# apps_rcm register map
Vendor: Texas Instruments
Peripheral module from a debugger description file (folder cc32).
Registers are 32-bit, read-write, no defined reset value unless marked. A register's access mark holds for its fields unless they carry their own. Offsets are as the file gives them; lines under a group give offsets from that group; [hi:lo] are bit positions; {n}, {i} and the like mark numbered series; 'fields as' and 'values as' point back to an identical list; <NAME> marks a mode.

## apps_rcm
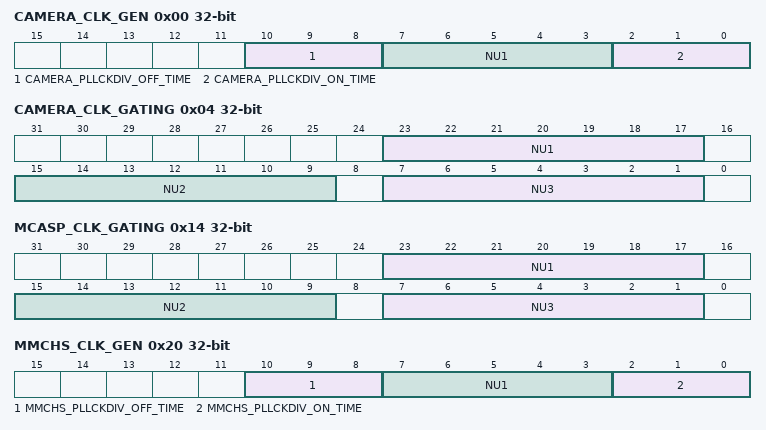
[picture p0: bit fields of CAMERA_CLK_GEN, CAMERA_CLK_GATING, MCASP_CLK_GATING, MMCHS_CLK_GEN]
0x00 CAMERA_CLK_GEN
  [10:8] CAMERA_PLLCKDIV_OFF_TIME — Configuration of OFF-TIME for dividing PLL clk (240 MHz) in generation of Camera func-clk : "000" - 1 "001" - 2 "010" - 3 "011" - 4 "100" - 5 "101" - 6 "110" - 7 "111" - 8
  [7:3] NU1
  [2:0] CAMERA_PLLCKDIV_ON_TIME — Configuration of ON-TIME for dividing PLL clk (240 MHz) in generation of Camera func-clk : "000" - 1 "001" - 2 "010" - 3 "011" - 4 "100" - 5 "101" - 6 "110" - 7 "111" - 8
0x04 CAMERA_CLK_GATING
  [23:17] NU1, [15:9] NU2, [7:1] NU3
0x08 CAMERA_SOFT_RESET access not given
0x14 MCASP_CLK_GATING
  [23:17] NU1, [15:9] NU2, [7:1] NU3
0x18 MCASP_SOFT_RESET access not given
0x20 MMCHS_CLK_GEN
  [10:8] MMCHS_PLLCKDIV_OFF_TIME — Configuration of OFF-TIME for dividing PLL clk (240 MHz) in generation of MMCHS func-clk : "000" - 1 "001" - 2 "010" - 3 "011" - 4 "100" - 5 "101" - 6 "110" - 7 "111" - 8
  [7:3] NU1
  [2:0] MMCHS_PLLCKDIV_ON_TIME — Configuration of ON-TIME for dividing PLL clk (240 MHz) in generation of MMCHS func-clk : "000" - 1 "001" - 2 "010" - 3 "011" - 4 "100" - 5 "101" - 6 "110" - 7 "111" - 8
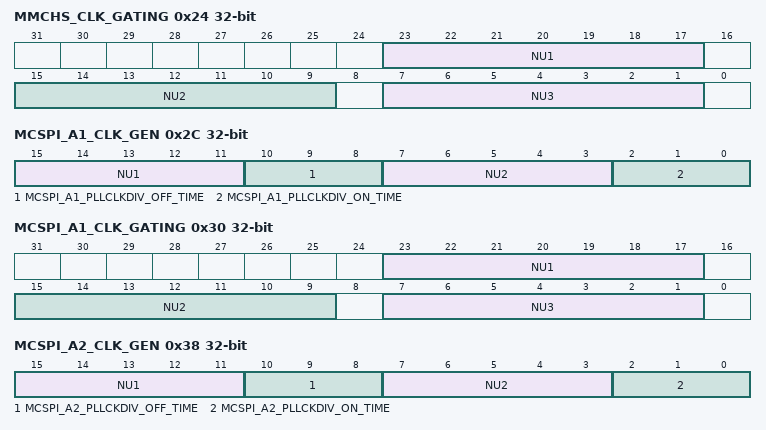
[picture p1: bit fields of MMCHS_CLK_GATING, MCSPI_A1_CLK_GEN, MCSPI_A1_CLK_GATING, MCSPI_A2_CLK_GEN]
0x24 MMCHS_CLK_GATING
  [23:17] NU1, [15:9] NU2, [7:1] NU3
0x28 MMCHS_SOFT_RESET access not given
0x2C MCSPI_A1_CLK_GEN
  [15:11] NU1
  [10:8] MCSPI_A1_PLLCLKDIV_OFF_TIME — Configuration of OFF-TIME for dividing PLL clk (240 MHz) in generation of MCSPI_A1 func-clk : "000" - 1 "001" - 2 "010" - 3 "011" - 4 "100" - 5 "101" - 6 "110" - 7 "111" - 8
  [7:3] NU2
  [2:0] MCSPI_A1_PLLCLKDIV_ON_TIME — Configuration of ON-TIME for dividing PLL clk (240 MHz) in generation of MCSPI_A1 func-clk : "000" - 1 "001" - 2 "010" - 3 "011" - 4 "100" - 5 "101" - 6 "110" - 7 "111" - 8
0x30 MCSPI_A1_CLK_GATING
  [23:17] NU1, [15:9] NU2, [7:1] NU3
0x34 MCSPI_A1_SOFT_RESET access not given
0x38 MCSPI_A2_CLK_GEN
  [15:11] NU1
  [10:8] MCSPI_A2_PLLCKDIV_OFF_TIME — Configuration of OFF-TIME for dividing PLL clk (240 MHz) in generation of MCSPI_A2 func-clk : "000" - 1 "001" - 2 "010" - 3 "011" - 4 "100" - 5 "101" - 6 "110" - 7 "111" - 8
  [7:3] NU2
  [2:0] MCSPI_A2_PLLCKDIV_ON_TIME — Configuration of OFF-TIME for dividing PLL clk (240 MHz) in generation of MCSPI_A2 func-clk : "000" - 1 "001" - 2 "010" - 3 "011" - 4 "100" - 5 "101" - 6 "110" - 7 "111" - 8
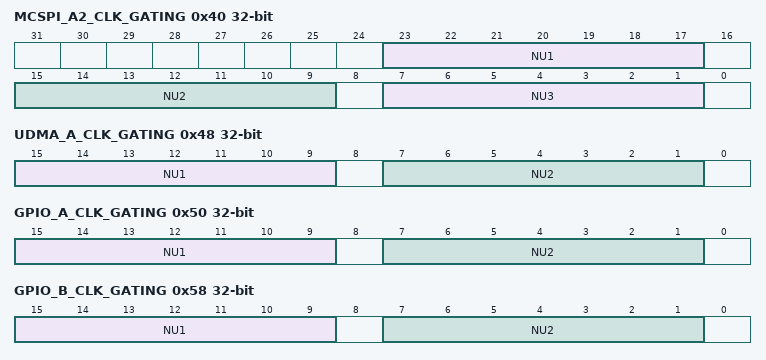
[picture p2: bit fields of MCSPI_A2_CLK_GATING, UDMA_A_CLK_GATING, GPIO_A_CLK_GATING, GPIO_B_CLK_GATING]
0x40 MCSPI_A2_CLK_GATING
  [23:17] NU1, [15:9] NU2, [7:1] NU3
0x44 MCSPI_A2_SOFT_RESET access not given
0x48 UDMA_A_CLK_GATING
  [15:9] NU1, [7:1] NU2
0x4C UDMA_A_SOFT_RESET access not given
0x50 GPIO_A_CLK_GATING
  [15:9] NU1, [7:1] NU2
0x54 GPIO_A_SOFT_RESET access not given
0x58 GPIO_B_CLK_GATING
  [15:9] NU1, [7:1] NU2
0x5C GPIO_B_SOFT_RESET access not given
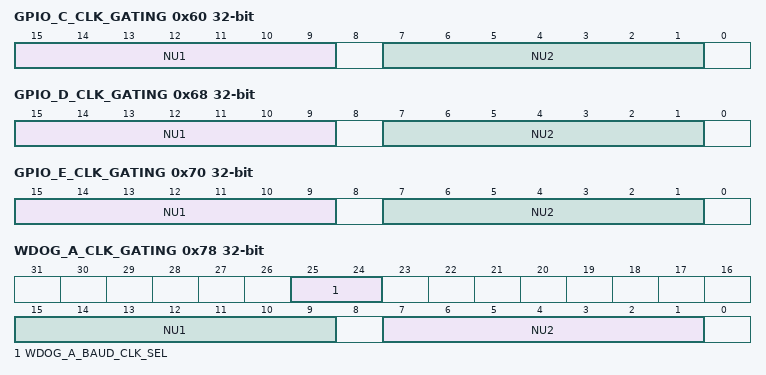
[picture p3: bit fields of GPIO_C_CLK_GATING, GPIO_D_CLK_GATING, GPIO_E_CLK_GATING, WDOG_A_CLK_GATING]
0x60 GPIO_C_CLK_GATING
  [15:9] NU1, [7:1] NU2
0x64 GPIO_C_SOFT_RESET access not given
0x68 GPIO_D_CLK_GATING
  [15:9] NU1, [7:1] NU2
0x6C GPIO_D_SOFT_RESET access not given
0x70 GPIO_E_CLK_GATING
  [15:9] NU1, [7:1] NU2
0x74 GPIO_E_SOFT_RESET access not given
0x78 WDOG_A_CLK_GATING
  [25:24] WDOG_A_BAUD_CLK_SEL — "00" - Sysclk ; "01" - REF_CLK (38.4 MHz) ; "10/11" - Slow_clk
  [15:9] NU1
  [7:1] NU2
0x7C WDOG_A_SOFT_RESET access not given
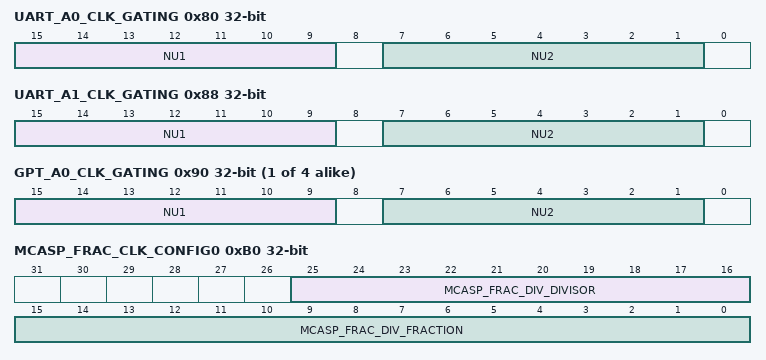
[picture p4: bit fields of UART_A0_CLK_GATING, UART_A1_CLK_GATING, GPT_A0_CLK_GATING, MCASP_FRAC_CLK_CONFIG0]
0x80 UART_A0_CLK_GATING
  [15:9] NU1, [7:1] NU2
0x84 UART_A0_SOFT_RESET access not given
0x88 UART_A1_CLK_GATING
  [15:9] NU1, [7:1] NU2
0x8C UART_A1_SOFT_RESET access not given
{0x90+8i} GPT_A{i}_CLK_GATING (i=0..3)
  [15:9] NU1, [7:1] NU2
{0x94+8i} GPT_A{i}_SOFT_RESET access not given (i=0..3)
0xB0 MCASP_FRAC_CLK_CONFIG0
  [25:16] MCASP_FRAC_DIV_DIVISOR, [15:0] MCASP_FRAC_DIV_FRACTION
0xB4 MCASP_FRAC_CLK_CONFIG1
  [9:0] MCASP_FRAC_DIV_PERIOD
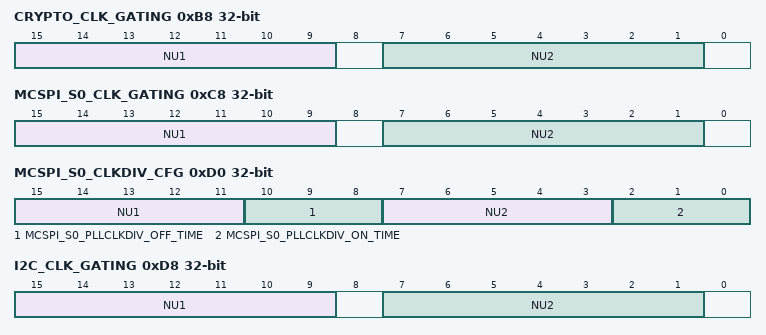
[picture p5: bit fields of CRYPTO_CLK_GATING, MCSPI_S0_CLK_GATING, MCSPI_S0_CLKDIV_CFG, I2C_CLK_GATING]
0xB8 CRYPTO_CLK_GATING
  [15:9] NU1, [7:1] NU2
0xBC CRYPTO_SOFT_RESET access not given
0xC8 MCSPI_S0_CLK_GATING
  [15:9] NU1, [7:1] NU2
0xCC MCSPI_S0_SOFT_RESET access not given
0xD0 MCSPI_S0_CLKDIV_CFG
  [15:11] NU1
  [10:8] MCSPI_S0_PLLCLKDIV_OFF_TIME — Configuration of OFF-TIME for dividing PLL clk (240 MHz) in generation of MCSPI_S0 func-clk : "000" - 1 "001" - 2 "010" - 3 "011" - 4 "100" - 5 "101" - 6 "110" - 7 "111" - 8
  [7:3] NU2
  [2:0] MCSPI_S0_PLLCLKDIV_ON_TIME — Configuration of ON-TIME for dividing PLL clk (240 MHz) in generation of MCSPI_S0 func-clk : "000" - 1 "001" - 2 "010" - 3 "011" - 4 "100" - 5 "101" - 6 "110" - 7 "111" - 8
0xD8 I2C_CLK_GATING
  [15:9] NU1, [7:1] NU2
0xDC I2C_SOFT_RESET access not given
0xE4 APPS_LPDS_REQ access not given
0xEC APPS_TURBO_REQ access not given
0x108 APPS_DSLP_WAKE_CONFIG access not given
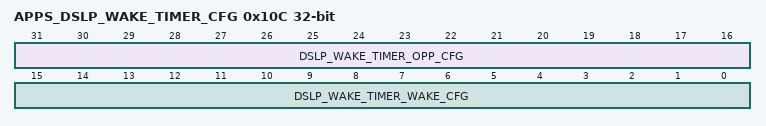
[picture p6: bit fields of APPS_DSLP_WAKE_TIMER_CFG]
0x10C APPS_DSLP_WAKE_TIMER_CFG
  [31:16] DSLP_WAKE_TIMER_OPP_CFG — Configuration (in slow_clks) which says when to request for OPP during deep-sleep exit
  [15:0] DSLP_WAKE_TIMER_WAKE_CFG — Configuration (in slow_clks) which says when to request for WAKE during deep-sleep exit
0x110 SLP_WAKE_ENABLE access not given
0x114 APPS_SLP_WAKETIMER_CFG access not given
0x118 APPS_TO_NWP_WAKE_REQUEST access not given
0x120 INTERRUPT_STATUS access not given
0x124 INTERRUPT_ENABLE access not given
